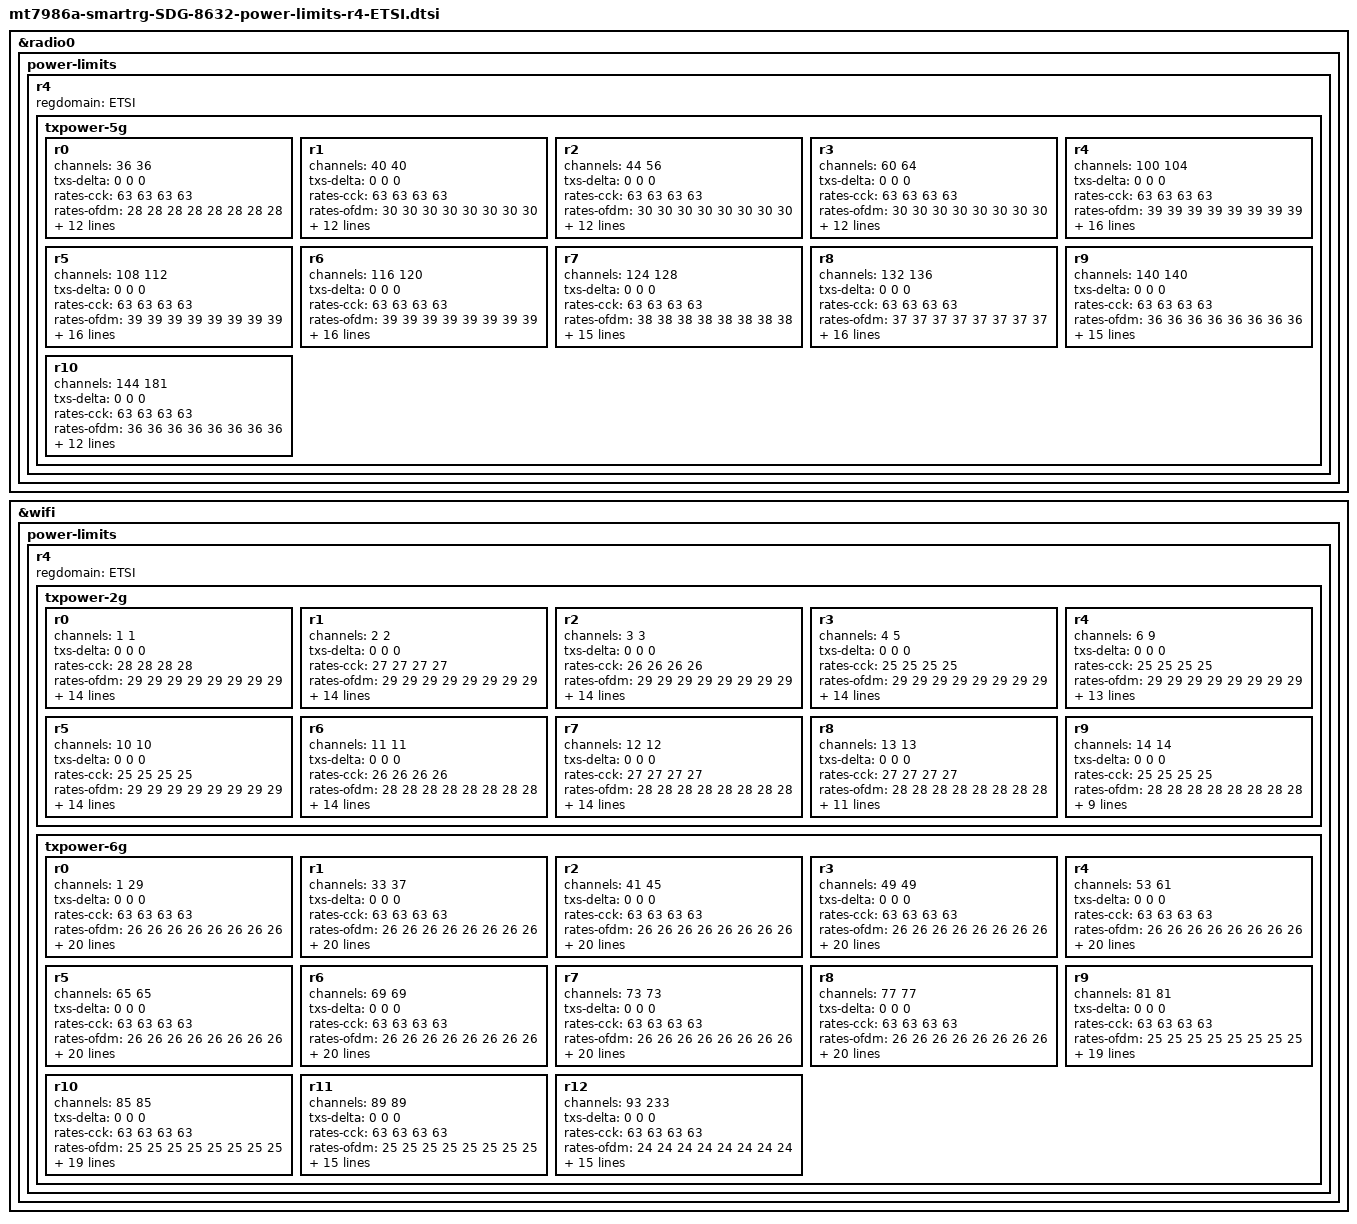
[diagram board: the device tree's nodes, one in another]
// SPDX-License-Identifier: (GPL-2.0 OR MIT)
/*
 * Copyright (C) 2022 SmartRG Inc.
 * Author: Chad Monroe <chad.monroe@smartrg.com>
 */

&radio0 {
	power-limits {
		r4 {
			regdomain = "ETSI";

			txpower-5g {
				r0 {
					channels = <36 36>;
					txs-delta = <0 0 0>;
					rates-cck = /bits/ 8 <63 63 63 63>;
					rates-ofdm = /bits/ 8 <28 28 28 28 28 28 28 28>;
					rates-mcs =
					/bits/ 8 <2 34 34 34 34 34 34 34 34 34 34>,
					/bits/ 8 <2 33 33 33 33 33 33 33 33 33 33>;
					rates-ru =
					/bits/ 8 <5 34 34 34 34 34 34 34 34 34 34 34 34>,
					/bits/ 8 <2 33 33 33 33 33 33 33 33 33 33 33 33>;
					paths-ofdm = /bits/ 8 <28 28 28 28>;
					paths-ofdm-bf = /bits/ 8 <0 28 28 28>;
					paths-ru =
					/bits/ 8 <5 34 34 34 34 34 34 34 34 34 34>,
					/bits/ 8 <2 33 33 33 33 33 33 33 33 33 33>;
					paths-ru-bf =
					/bits/ 8 <3 31 31 31 31 31 31 31 31 31 31>,
					/bits/ 8 <2 0 31 31 31 31 31 31 31 31 31>,
					/bits/ 8 <2 0 30 30 30 30 30 30 30 30 30>;
				};
				r1 {
					channels = <40 40>;
					txs-delta = <0 0 0>;
					rates-cck = /bits/ 8 <63 63 63 63>;
					rates-ofdm = /bits/ 8 <30 30 30 30 30 30 30 30>;
					rates-mcs =
					/bits/ 8 <2 34 34 34 34 34 34 34 34 34 34>,
					/bits/ 8 <2 33 33 33 33 33 33 33 33 33 33>;
					rates-ru =
					/bits/ 8 <5 34 34 34 34 34 34 34 34 34 34 34 34>,
					/bits/ 8 <2 33 33 33 33 33 33 33 33 33 33 33 33>;
					paths-ofdm = /bits/ 8 <30 30 30 30>;
					paths-ofdm-bf = /bits/ 8 <0 30 30 30>;
					paths-ru =
					/bits/ 8 <5 34 34 34 34 34 34 34 34 34 34>,
					/bits/ 8 <2 33 33 33 33 33 33 33 33 33 33>;
					paths-ru-bf =
					/bits/ 8 <3 31 31 31 31 31 31 31 31 31 31>,
					/bits/ 8 <2 0 31 31 31 31 31 31 31 31 31>,
					/bits/ 8 <2 0 30 30 30 30 30 30 30 30 30>;
				};
				r2 {
					channels = <44 56>;
					txs-delta = <0 0 0>;
					rates-cck = /bits/ 8 <63 63 63 63>;
					rates-ofdm = /bits/ 8 <30 30 30 30 30 30 30 30>;
					rates-mcs =
					/bits/ 8 <2 34 34 34 34 34 34 34 34 34 34>,
					/bits/ 8 <2 33 33 33 33 33 33 33 33 33 33>;
					rates-ru =
					/bits/ 8 <5 34 34 34 34 34 34 34 34 34 34 34 34>,
					/bits/ 8 <2 33 33 33 33 33 33 33 33 33 33 33 33>;
					paths-ofdm = /bits/ 8 <30 30 30 30>;
					paths-ofdm-bf = /bits/ 8 <0 30 30 30>;
					paths-ru =
					/bits/ 8 <5 34 34 34 34 34 34 34 34 34 34>,
					/bits/ 8 <2 33 33 33 33 33 33 33 33 33 33>;
					paths-ru-bf =
					/bits/ 8 <3 31 31 31 31 31 31 31 31 31 31>,
					/bits/ 8 <1 0 31 31 31 31 31 31 31 31 31>,
					/bits/ 8 <3 0 30 30 30 30 30 30 30 30 30>;
				};
				r3 {
					channels = <60 64>;
					txs-delta = <0 0 0>;
					rates-cck = /bits/ 8 <63 63 63 63>;
					rates-ofdm = /bits/ 8 <30 30 30 30 30 30 30 30>;
					rates-mcs =
					/bits/ 8 <1 34 34 34 34 34 34 34 34 34 34>,
					/bits/ 8 <3 33 33 33 33 33 33 33 33 33 33>;
					rates-ru =
					/bits/ 8 <4 34 34 34 34 34 34 34 34 34 34 34 34>,
					/bits/ 8 <3 33 33 33 33 33 33 33 33 33 33 33 33>;
					paths-ofdm = /bits/ 8 <30 30 30 30>;
					paths-ofdm-bf = /bits/ 8 <0 30 30 30>;
					paths-ru =
					/bits/ 8 <4 34 34 34 34 34 34 34 34 34 34>,
					/bits/ 8 <3 33 33 33 33 33 33 33 33 33 33>;
					paths-ru-bf =
					/bits/ 8 <3 31 31 31 31 31 31 31 31 31 31>,
					/bits/ 8 <1 0 31 31 31 31 31 31 31 31 31>,
					/bits/ 8 <3 0 30 30 30 30 30 30 30 30 30>;
				};
				r4 {
					channels = <100 104>;
					txs-delta = <0 0 0>;
					rates-cck = /bits/ 8 <63 63 63 63>;
					rates-ofdm = /bits/ 8 <39 39 39 39 39 39 39 39>;
					rates-mcs =
					/bits/ 8 <1 37 37 37 37 37 37 37 37 37 37>,
					/bits/ 8 <1 34 34 34 34 34 34 34 34 34 34>,
					/bits/ 8 <2 32 32 32 32 32 32 32 32 32 32>;
					rates-ru =
					/bits/ 8 <4 37 37 37 37 37 37 37 37 37 37 37 37>,
					/bits/ 8 <1 34 34 34 34 34 34 34 34 34 34 34 34>,
					/bits/ 8 <2 32 32 32 32 32 32 32 32 32 32 32 32>;
					paths-ofdm = /bits/ 8 <39 39 39 39>;
					paths-ofdm-bf = /bits/ 8 <0 39 39 39>;
					paths-ru =
					/bits/ 8 <4 37 37 37 37 37 37 37 37 37 37>,
					/bits/ 8 <1 34 34 34 34 34 34 34 34 34 34>,
					/bits/ 8 <2 32 32 32 32 32 32 32 32 32 32>;
					paths-ru-bf =
					/bits/ 8 <3 38 38 38 38 38 38 38 38 38 38>,
					/bits/ 8 <1 0 38 38 38 38 38 38 38 38 38>,
					/bits/ 8 <1 0 35 35 35 35 35 35 35 35 35>,
					/bits/ 8 <2 0 34 34 34 34 34 34 34 34 34>;
				};
				r5 {
					channels = <108 112>;
					txs-delta = <0 0 0>;
					rates-cck = /bits/ 8 <63 63 63 63>;
					rates-ofdm = /bits/ 8 <39 39 39 39 39 39 39 39>;
					rates-mcs =
					/bits/ 8 <1 37 37 37 37 37 37 37 37 37 37>,
					/bits/ 8 <1 35 35 35 35 35 35 35 35 35 35>,
					/bits/ 8 <2 32 32 32 32 32 32 32 32 32 32>;
					rates-ru =
					/bits/ 8 <4 37 37 37 37 37 37 37 37 37 37 37 37>,
					/bits/ 8 <1 35 35 35 35 35 35 35 35 35 35 35 35>,
					/bits/ 8 <2 32 32 32 32 32 32 32 32 32 32 32 32>;
					paths-ofdm = /bits/ 8 <39 39 39 39>;
					paths-ofdm-bf = /bits/ 8 <0 39 39 39>;
					paths-ru =
					/bits/ 8 <4 37 37 37 37 37 37 37 37 37 37>,
					/bits/ 8 <1 35 35 35 35 35 35 35 35 35 35>,
					/bits/ 8 <2 32 32 32 32 32 32 32 32 32 32>;
					paths-ru-bf =
					/bits/ 8 <3 38 38 38 38 38 38 38 38 38 38>,
					/bits/ 8 <1 0 38 38 38 38 38 38 38 38 38>,
					/bits/ 8 <1 0 36 36 36 36 36 36 36 36 36>,
					/bits/ 8 <2 0 34 34 34 34 34 34 34 34 34>;
				};
				r6 {
					channels = <116 120>;
					txs-delta = <0 0 0>;
					rates-cck = /bits/ 8 <63 63 63 63>;
					rates-ofdm = /bits/ 8 <39 39 39 39 39 39 39 39>;
					rates-mcs =
					/bits/ 8 <1 37 37 37 37 37 37 37 37 37 37>,
					/bits/ 8 <1 36 36 36 36 36 36 36 36 36 36>,
					/bits/ 8 <2 39 39 39 39 39 39 39 39 39 39>;
					rates-ru =
					/bits/ 8 <4 37 37 37 37 37 37 37 37 37 37 37 37>,
					/bits/ 8 <1 36 36 36 36 36 36 36 36 36 36 36 36>,
					/bits/ 8 <2 39 39 39 39 39 39 39 39 39 39 39 39>;
					paths-ofdm = /bits/ 8 <39 39 39 39>;
					paths-ofdm-bf = /bits/ 8 <0 39 39 39>;
					paths-ru =
					/bits/ 8 <4 37 37 37 37 37 37 37 37 37 37>,
					/bits/ 8 <1 36 36 36 36 36 36 36 36 36 36>,
					/bits/ 8 <2 39 39 39 39 39 39 39 39 39 39>;
					paths-ru-bf =
					/bits/ 8 <3 38 38 38 38 38 38 38 38 38 38>,
					/bits/ 8 <1 0 38 38 38 38 38 38 38 38 38>,
					/bits/ 8 <1 0 37 37 37 37 37 37 37 37 37>,
					/bits/ 8 <2 0 38 38 38 38 38 38 38 38 38>;
				};
				r7 {
					channels = <124 128>;
					txs-delta = <0 0 0>;
					rates-cck = /bits/ 8 <63 63 63 63>;
					rates-ofdm = /bits/ 8 <38 38 38 38 38 38 38 38>;
					rates-mcs =
					/bits/ 8 <1 36 36 36 36 36 36 36 36 36 36>,
					/bits/ 8 <1 37 37 37 37 37 37 37 37 37 37>,
					/bits/ 8 <2 39 39 39 39 39 39 39 39 39 39>;
					rates-ru =
					/bits/ 8 <4 36 36 36 36 36 36 36 36 36 36 36 36>,
					/bits/ 8 <1 37 37 37 37 37 37 37 37 37 37 37 37>,
					/bits/ 8 <2 39 39 39 39 39 39 39 39 39 39 39 39>;
					paths-ofdm = /bits/ 8 <38 38 38 38>;
					paths-ofdm-bf = /bits/ 8 <0 38 38 38>;
					paths-ru =
					/bits/ 8 <4 36 36 36 36 36 36 36 36 36 36>,
					/bits/ 8 <1 37 37 37 37 37 37 37 37 37 37>,
					/bits/ 8 <2 39 39 39 39 39 39 39 39 39 39>;
					paths-ru-bf =
					/bits/ 8 <3 37 37 37 37 37 37 37 37 37 37>,
					/bits/ 8 <1 0 37 37 37 37 37 37 37 37 37>,
					/bits/ 8 <3 0 38 38 38 38 38 38 38 38 38>;
				};
				r8 {
					channels = <132 136>;
					txs-delta = <0 0 0>;
					rates-cck = /bits/ 8 <63 63 63 63>;
					rates-ofdm = /bits/ 8 <37 37 37 37 37 37 37 37>;
					rates-mcs =
					/bits/ 8 <1 35 35 35 35 35 35 35 35 35 35>,
					/bits/ 8 <1 38 38 38 38 38 38 38 38 38 38>,
					/bits/ 8 <2 32 32 32 32 32 32 32 32 32 32>;
					rates-ru =
					/bits/ 8 <4 35 35 35 35 35 35 35 35 35 35 35 35>,
					/bits/ 8 <1 38 38 38 38 38 38 38 38 38 38 38 38>,
					/bits/ 8 <2 32 32 32 32 32 32 32 32 32 32 32 32>;
					paths-ofdm = /bits/ 8 <37 37 37 37>;
					paths-ofdm-bf = /bits/ 8 <0 37 37 37>;
					paths-ru =
					/bits/ 8 <4 35 35 35 35 35 35 35 35 35 35>,
					/bits/ 8 <1 38 38 38 38 38 38 38 38 38 38>,
					/bits/ 8 <2 32 32 32 32 32 32 32 32 32 32>;
					paths-ru-bf =
					/bits/ 8 <3 36 36 36 36 36 36 36 36 36 36>,
					/bits/ 8 <1 0 36 36 36 36 36 36 36 36 36>,
					/bits/ 8 <1 0 39 39 39 39 39 39 39 39 39>,
					/bits/ 8 <2 0 34 34 34 34 34 34 34 34 34>;
				};
				r9 {
					channels = <140 140>;
					txs-delta = <0 0 0>;
					rates-cck = /bits/ 8 <63 63 63 63>;
					rates-ofdm = /bits/ 8 <36 36 36 36 36 36 36 36>;
					rates-mcs =
					/bits/ 8 <1 34 34 34 34 34 34 34 34 34 34>,
					/bits/ 8 <1 38 38 38 38 38 38 38 38 38 38>,
					/bits/ 8 <2 32 32 32 32 32 32 32 32 32 32>;
					rates-ru =
					/bits/ 8 <4 34 34 34 34 34 34 34 34 34 34 34 34>,
					/bits/ 8 <1 38 38 38 38 38 38 38 38 38 38 38 38>,
					/bits/ 8 <2 32 32 32 32 32 32 32 32 32 32 32 32>;
					paths-ofdm = /bits/ 8 <36 36 36 36>;
					paths-ofdm-bf = /bits/ 8 <0 36 36 36>;
					paths-ru =
					/bits/ 8 <4 34 34 34 34 34 34 34 34 34 34>,
					/bits/ 8 <1 38 38 38 38 38 38 38 38 38 38>,
					/bits/ 8 <2 32 32 32 32 32 32 32 32 32 32>;
					paths-ru-bf =
					/bits/ 8 <3 35 35 35 35 35 35 35 35 35 35>,
					/bits/ 8 <2 0 35 35 35 35 35 35 35 35 35>,
					/bits/ 8 <2 0 34 34 34 34 34 34 34 34 34>;
				};
				r10 {
					channels = <144 181>;
					txs-delta = <0 0 0>;
					rates-cck = /bits/ 8 <63 63 63 63>;
					rates-ofdm = /bits/ 8 <36 36 36 36 36 36 36 36>;
					rates-mcs =
					/bits/ 8 <2 34 34 34 34 34 34 34 34 34 34>,
					/bits/ 8 <2 32 32 32 32 32 32 32 32 32 32>;
					rates-ru =
					/bits/ 8 <5 34 34 34 34 34 34 34 34 34 34 34 34>,
					/bits/ 8 <2 32 32 32 32 32 32 32 32 32 32 32 32>;
					paths-ofdm = /bits/ 8 <36 36 36 36>;
					paths-ofdm-bf = /bits/ 8 <0 36 36 36>;
					paths-ru =
					/bits/ 8 <5 34 34 34 34 34 34 34 34 34 34>,
					/bits/ 8 <2 32 32 32 32 32 32 32 32 32 32>;
					paths-ru-bf =
					/bits/ 8 <3 35 35 35 35 35 35 35 35 35 35>,
					/bits/ 8 <2 0 35 35 35 35 35 35 35 35 35>,
					/bits/ 8 <2 0 34 34 34 34 34 34 34 34 34>;
				};
			};
		};
	};
};

&wifi {
	power-limits {
		r4 {
			regdomain = "ETSI";

			txpower-2g {
				r0 {
					channels = <1 1>;
					txs-delta = <0 0 0>;
					rates-cck = /bits/ 8 <28 28 28 28>;
					rates-ofdm = /bits/ 8 <29 29 29 29 29 29 29 29>;
					rates-mcs =
					/bits/ 8 <1 29 29 29 29 29 29 29 29 29 29>,
					/bits/ 8 <3 31 31 31 31 31 31 31 31 31 31>;
					rates-ru =
					/bits/ 8 <4 29 29 29 29 29 29 29 29 29 29 29 29>,
					/bits/ 8 <3 31 31 31 31 31 31 31 31 31 31 31 31>;
					paths-cck = /bits/ 8 <28 28 28 28>;
					paths-ofdm = /bits/ 8 <29 29 29 29>;
					paths-ofdm-bf = /bits/ 8 <0 29 29 29>;
					paths-ru =
					/bits/ 8 <4 29 29 29 29 29 29 29 29 29 29>,
					/bits/ 8 <1 31 31 31 31 31 31 31 31 31 31>,
					/bits/ 8 <2 27 27 27 27 27 27 27 27 27 27>;
					paths-ru-bf =
					/bits/ 8 <3 26 26 26 26 26 26 26 26 26 26>,
					/bits/ 8 <1 0 26 26 26 26 26 26 26 26 26>,
					/bits/ 8 <3 0 27 27 27 27 27 27 27 27 27>;
				};
				r1 {
					channels = <2 2>;
					txs-delta = <0 0 0>;
					rates-cck = /bits/ 8 <27 27 27 27>;
					rates-ofdm = /bits/ 8 <29 29 29 29 29 29 29 29>;
					rates-mcs =
					/bits/ 8 <1 29 29 29 29 29 29 29 29 29 29>,
					/bits/ 8 <3 31 31 31 31 31 31 31 31 31 31>;
					rates-ru =
					/bits/ 8 <4 29 29 29 29 29 29 29 29 29 29 29 29>,
					/bits/ 8 <3 31 31 31 31 31 31 31 31 31 31 31 31>;
					paths-cck = /bits/ 8 <27 27 27 27>;
					paths-ofdm = /bits/ 8 <29 29 29 29>;
					paths-ofdm-bf = /bits/ 8 <0 29 29 29>;
					paths-ru =
					/bits/ 8 <4 29 29 29 29 29 29 29 29 29 29>,
					/bits/ 8 <1 31 31 31 31 31 31 31 31 31 31>,
					/bits/ 8 <2 27 27 27 27 27 27 27 27 27 27>;
					paths-ru-bf =
					/bits/ 8 <3 26 26 26 26 26 26 26 26 26 26>,
					/bits/ 8 <1 0 26 26 26 26 26 26 26 26 26>,
					/bits/ 8 <3 0 27 27 27 27 27 27 27 27 27>;
				};
				r2 {
					channels = <3 3>;
					txs-delta = <0 0 0>;
					rates-cck = /bits/ 8 <26 26 26 26>;
					rates-ofdm = /bits/ 8 <29 29 29 29 29 29 29 29>;
					rates-mcs =
					/bits/ 8 <1 29 29 29 29 29 29 29 29 29 29>,
					/bits/ 8 <3 31 31 31 31 31 31 31 31 31 31>;
					rates-ru =
					/bits/ 8 <4 29 29 29 29 29 29 29 29 29 29 29 29>,
					/bits/ 8 <3 31 31 31 31 31 31 31 31 31 31 31 31>;
					paths-cck = /bits/ 8 <26 26 26 26>;
					paths-ofdm = /bits/ 8 <29 29 29 29>;
					paths-ofdm-bf = /bits/ 8 <0 29 29 29>;
					paths-ru =
					/bits/ 8 <4 29 29 29 29 29 29 29 29 29 29>,
					/bits/ 8 <1 31 31 31 31 31 31 31 31 31 31>,
					/bits/ 8 <2 27 27 27 27 27 27 27 27 27 27>;
					paths-ru-bf =
					/bits/ 8 <3 26 26 26 26 26 26 26 26 26 26>,
					/bits/ 8 <1 0 26 26 26 26 26 26 26 26 26>,
					/bits/ 8 <3 0 27 27 27 27 27 27 27 27 27>;
				};
				r3 {
					channels = <4 5>;
					txs-delta = <0 0 0>;
					rates-cck = /bits/ 8 <25 25 25 25>;
					rates-ofdm = /bits/ 8 <29 29 29 29 29 29 29 29>;
					rates-mcs =
					/bits/ 8 <1 29 29 29 29 29 29 29 29 29 29>,
					/bits/ 8 <3 31 31 31 31 31 31 31 31 31 31>;
					rates-ru =
					/bits/ 8 <4 29 29 29 29 29 29 29 29 29 29 29 29>,
					/bits/ 8 <3 31 31 31 31 31 31 31 31 31 31 31 31>;
					paths-cck = /bits/ 8 <25 25 25 25>;
					paths-ofdm = /bits/ 8 <29 29 29 29>;
					paths-ofdm-bf = /bits/ 8 <0 29 29 29>;
					paths-ru =
					/bits/ 8 <4 29 29 29 29 29 29 29 29 29 29>,
					/bits/ 8 <1 31 31 31 31 31 31 31 31 31 31>,
					/bits/ 8 <2 26 26 26 26 26 26 26 26 26 26>;
					paths-ru-bf =
					/bits/ 8 <3 25 25 25 25 25 25 25 25 25 25>,
					/bits/ 8 <1 0 25 25 25 25 25 25 25 25 25>,
					/bits/ 8 <3 0 26 26 26 26 26 26 26 26 26>;
				};
				r4 {
					channels = <6 9>;
					txs-delta = <0 0 0>;
					rates-cck = /bits/ 8 <25 25 25 25>;
					rates-ofdm = /bits/ 8 <29 29 29 29 29 29 29 29>;
					rates-mcs =
					/bits/ 8 <1 28 28 28 28 28 28 28 28 28 28>,
					/bits/ 8 <3 30 30 30 30 30 30 30 30 30 30>;
					rates-ru =
					/bits/ 8 <4 28 28 28 28 28 28 28 28 28 28 28 28>,
					/bits/ 8 <3 30 30 30 30 30 30 30 30 30 30 30 30>;
					paths-cck = /bits/ 8 <25 25 25 25>;
					paths-ofdm = /bits/ 8 <29 29 29 29>;
					paths-ofdm-bf = /bits/ 8 <0 29 29 29>;
					paths-ru =
					/bits/ 8 <4 28 28 28 28 28 28 28 28 28 28>,
					/bits/ 8 <1 30 30 30 30 30 30 30 30 30 30>,
					/bits/ 8 <2 25 25 25 25 25 25 25 25 25 25>;
					paths-ru-bf =
					/bits/ 8 <3 25 25 25 25 25 25 25 25 25 25>,
					/bits/ 8 <4 0 25 25 25 25 25 25 25 25 25>;
				};
				r5 {
					channels = <10 10>;
					txs-delta = <0 0 0>;
					rates-cck = /bits/ 8 <25 25 25 25>;
					rates-ofdm = /bits/ 8 <29 29 29 29 29 29 29 29>;
					rates-mcs =
					/bits/ 8 <1 28 28 28 28 28 28 28 28 28 28>,
					/bits/ 8 <3 30 30 30 30 30 30 30 30 30 30>;
					rates-ru =
					/bits/ 8 <4 28 28 28 28 28 28 28 28 28 28 28 28>,
					/bits/ 8 <3 30 30 30 30 30 30 30 30 30 30 30 30>;
					paths-cck = /bits/ 8 <25 25 25 25>;
					paths-ofdm = /bits/ 8 <29 29 29 29>;
					paths-ofdm-bf = /bits/ 8 <0 29 29 29>;
					paths-ru =
					/bits/ 8 <4 28 28 28 28 28 28 28 28 28 28>,
					/bits/ 8 <1 30 30 30 30 30 30 30 30 30 30>,
					/bits/ 8 <2 26 26 26 26 26 26 26 26 26 26>;
					paths-ru-bf =
					/bits/ 8 <3 25 25 25 25 25 25 25 25 25 25>,
					/bits/ 8 <1 0 25 25 25 25 25 25 25 25 25>,
					/bits/ 8 <3 0 26 26 26 26 26 26 26 26 26>;
				};
				r6 {
					channels = <11 11>;
					txs-delta = <0 0 0>;
					rates-cck = /bits/ 8 <26 26 26 26>;
					rates-ofdm = /bits/ 8 <28 28 28 28 28 28 28 28>;
					rates-mcs =
					/bits/ 8 <1 28 28 28 28 28 28 28 28 28 28>,
					/bits/ 8 <3 30 30 30 30 30 30 30 30 30 30>;
					rates-ru =
					/bits/ 8 <4 28 28 28 28 28 28 28 28 28 28 28 28>,
					/bits/ 8 <3 30 30 30 30 30 30 30 30 30 30 30 30>;
					paths-cck = /bits/ 8 <26 26 26 26>;
					paths-ofdm = /bits/ 8 <28 28 28 28>;
					paths-ofdm-bf = /bits/ 8 <0 28 28 28>;
					paths-ru =
					/bits/ 8 <4 28 28 28 28 28 28 28 28 28 28>,
					/bits/ 8 <1 30 30 30 30 30 30 30 30 30 30>,
					/bits/ 8 <2 26 26 26 26 26 26 26 26 26 26>;
					paths-ru-bf =
					/bits/ 8 <3 25 25 25 25 25 25 25 25 25 25>,
					/bits/ 8 <1 0 25 25 25 25 25 25 25 25 25>,
					/bits/ 8 <3 0 26 26 26 26 26 26 26 26 26>;
				};
				r7 {
					channels = <12 12>;
					txs-delta = <0 0 0>;
					rates-cck = /bits/ 8 <27 27 27 27>;
					rates-ofdm = /bits/ 8 <28 28 28 28 28 28 28 28>;
					rates-mcs =
					/bits/ 8 <1 28 28 28 28 28 28 28 28 28 28>,
					/bits/ 8 <3 29 29 29 29 29 29 29 29 29 29>;
					rates-ru =
					/bits/ 8 <4 28 28 28 28 28 28 28 28 28 28 28 28>,
					/bits/ 8 <3 29 29 29 29 29 29 29 29 29 29 29 29>;
					paths-cck = /bits/ 8 <27 27 27 27>;
					paths-ofdm = /bits/ 8 <28 28 28 28>;
					paths-ofdm-bf = /bits/ 8 <0 28 28 28>;
					paths-ru =
					/bits/ 8 <4 28 28 28 28 28 28 28 28 28 28>,
					/bits/ 8 <1 29 29 29 29 29 29 29 29 29 29>,
					/bits/ 8 <2 26 26 26 26 26 26 26 26 26 26>;
					paths-ru-bf =
					/bits/ 8 <3 25 25 25 25 25 25 25 25 25 25>,
					/bits/ 8 <1 0 25 25 25 25 25 25 25 25 25>,
					/bits/ 8 <3 0 26 26 26 26 26 26 26 26 26>;
				};
				r8 {
					channels = <13 13>;
					txs-delta = <0 0 0>;
					rates-cck = /bits/ 8 <27 27 27 27>;
					rates-ofdm = /bits/ 8 <28 28 28 28 28 28 28 28>;
					rates-mcs =
					/bits/ 8 <4 28 28 28 28 28 28 28 28 28 28>;
					rates-ru =
					/bits/ 8 <7 28 28 28 28 28 28 28 28 28 28 28 28>;
					paths-cck = /bits/ 8 <27 27 27 27>;
					paths-ofdm = /bits/ 8 <28 28 28 28>;
					paths-ofdm-bf = /bits/ 8 <0 28 28 28>;
					paths-ru =
					/bits/ 8 <5 28 28 28 28 28 28 28 28 28 28>,
					/bits/ 8 <2 26 26 26 26 26 26 26 26 26 26>;
					paths-ru-bf =
					/bits/ 8 <3 25 25 25 25 25 25 25 25 25 25>,
					/bits/ 8 <1 0 25 25 25 25 25 25 25 25 25>,
					/bits/ 8 <3 0 26 26 26 26 26 26 26 26 26>;
				};
				r9 {
					channels = <14 14>;
					txs-delta = <0 0 0>;
					rates-cck = /bits/ 8 <25 25 25 25>;
					rates-ofdm = /bits/ 8 <28 28 28 28 28 28 28 28>;
					rates-mcs =
					/bits/ 8 <4 28 28 28 28 28 28 28 28 28 28>;
					rates-ru =
					/bits/ 8 <7 28 28 28 28 28 28 28 28 28 28 28 28>;
					paths-cck = /bits/ 8 <25 25 25 25>;
					paths-ofdm = /bits/ 8 <25 25 25 25>;
					paths-ofdm-bf = /bits/ 8 <0 25 25 25>;
					paths-ru =
					/bits/ 8 <7 25 25 25 25 25 25 25 25 25 25>;
					paths-ru-bf =
					/bits/ 8 <3 25 25 25 25 25 25 25 25 25 25>,
					/bits/ 8 <4 0 25 25 25 25 25 25 25 25 25>;
				};
			};

			txpower-6g {
				r0 {
					channels = <1 29>;
					txs-delta = <0 0 0>;
					rates-cck = /bits/ 8 <63 63 63 63>;
					rates-ofdm = /bits/ 8 <26 26 26 26 26 26 26 26>;
					rates-mcs =
					/bits/ 8 <1 29 29 29 29 29 29 29 29 29 29>,
					/bits/ 8 <1 31 31 31 31 31 31 31 31 31 31>,
					/bits/ 8 <1 29 29 29 29 29 29 29 29 29 29>,
					/bits/ 8 <1 31 31 31 31 31 31 31 31 31 31>;
					rates-ru =
					/bits/ 8 <4 29 29 29 29 29 29 29 29 29 29 29 29>,
					/bits/ 8 <1 31 31 31 31 31 31 31 31 31 31 31 31>,
					/bits/ 8 <1 29 29 29 29 29 29 29 29 29 29 29 29>,
					/bits/ 8 <1 31 31 31 31 31 31 31 31 31 31 31 31>;
					paths-ofdm = /bits/ 8 <26 26 26 26>;
					paths-ofdm-bf = /bits/ 8 <0 26 26 26>;
					paths-ru =
					/bits/ 8 <4 29 29 29 29 29 29 29 29 29 29>,
					/bits/ 8 <1 31 31 31 31 31 31 31 31 31 31>,
					/bits/ 8 <1 29 29 29 29 29 29 29 29 29 29>,
					/bits/ 8 <1 31 31 31 31 31 31 31 31 31 31>;
					paths-ru-bf =
					/bits/ 8 <3 20 20 20 20 20 20 20 20 20 20>,
					/bits/ 8 <1 0 20 20 20 20 20 20 20 20 20>,
					/bits/ 8 <1 0 21 21 21 21 21 21 21 21 21>,
					/bits/ 8 <1 0 20 20 20 20 20 20 20 20 20>,
					/bits/ 8 <1 0 22 22 22 22 22 22 22 22 22>;
				};
				r1 {
					channels = <33 37>;
					txs-delta = <0 0 0>;
					rates-cck = /bits/ 8 <63 63 63 63>;
					rates-ofdm = /bits/ 8 <26 26 26 26 26 26 26 26>;
					rates-mcs =
					/bits/ 8 <1 29 29 29 29 29 29 29 29 29 29>,
					/bits/ 8 <1 31 31 31 31 31 31 31 31 31 31>,
					/bits/ 8 <1 29 29 29 29 29 29 29 29 29 29>,
					/bits/ 8 <1 31 31 31 31 31 31 31 31 31 31>;
					rates-ru =
					/bits/ 8 <4 29 29 29 29 29 29 29 29 29 29 29 29>,
					/bits/ 8 <1 31 31 31 31 31 31 31 31 31 31 31 31>,
					/bits/ 8 <1 29 29 29 29 29 29 29 29 29 29 29 29>,
					/bits/ 8 <1 31 31 31 31 31 31 31 31 31 31 31 31>;
					paths-ofdm = /bits/ 8 <26 26 26 26>;
					paths-ofdm-bf = /bits/ 8 <0 26 26 26>;
					paths-ru =
					/bits/ 8 <4 29 29 29 29 29 29 29 29 29 29>,
					/bits/ 8 <1 31 31 31 31 31 31 31 31 31 31>,
					/bits/ 8 <1 29 29 29 29 29 29 29 29 29 29>,
					/bits/ 8 <1 31 31 31 31 31 31 31 31 31 31>;
					paths-ru-bf =
					/bits/ 8 <3 20 20 20 20 20 20 20 20 20 20>,
					/bits/ 8 <1 0 20 20 20 20 20 20 20 20 20>,
					/bits/ 8 <1 0 21 21 21 21 21 21 21 21 21>,
					/bits/ 8 <1 0 20 20 20 20 20 20 20 20 20>,
					/bits/ 8 <1 0 21 21 21 21 21 21 21 21 21>;
				};
				r2 {
					channels = <41 45>;
					txs-delta = <0 0 0>;
					rates-cck = /bits/ 8 <63 63 63 63>;
					rates-ofdm = /bits/ 8 <26 26 26 26 26 26 26 26>;
					rates-mcs =
					/bits/ 8 <1 29 29 29 29 29 29 29 29 29 29>,
					/bits/ 8 <1 30 30 30 30 30 30 30 30 30 30>,
					/bits/ 8 <1 29 29 29 29 29 29 29 29 29 29>,
					/bits/ 8 <1 31 31 31 31 31 31 31 31 31 31>;
					rates-ru =
					/bits/ 8 <4 29 29 29 29 29 29 29 29 29 29 29 29>,
					/bits/ 8 <1 30 30 30 30 30 30 30 30 30 30 30 30>,
					/bits/ 8 <1 29 29 29 29 29 29 29 29 29 29 29 29>,
					/bits/ 8 <1 31 31 31 31 31 31 31 31 31 31 31 31>;
					paths-ofdm = /bits/ 8 <26 26 26 26>;
					paths-ofdm-bf = /bits/ 8 <0 26 26 26>;
					paths-ru =
					/bits/ 8 <4 29 29 29 29 29 29 29 29 29 29>,
					/bits/ 8 <1 30 30 30 30 30 30 30 30 30 30>,
					/bits/ 8 <1 29 29 29 29 29 29 29 29 29 29>,
					/bits/ 8 <1 31 31 31 31 31 31 31 31 31 31>;
					paths-ru-bf =
					/bits/ 8 <3 20 20 20 20 20 20 20 20 20 20>,
					/bits/ 8 <1 0 20 20 20 20 20 20 20 20 20>,
					/bits/ 8 <1 0 21 21 21 21 21 21 21 21 21>,
					/bits/ 8 <1 0 20 20 20 20 20 20 20 20 20>,
					/bits/ 8 <1 0 21 21 21 21 21 21 21 21 21>;
				};
				r3 {
					channels = <49 49>;
					txs-delta = <0 0 0>;
					rates-cck = /bits/ 8 <63 63 63 63>;
					rates-ofdm = /bits/ 8 <26 26 26 26 26 26 26 26>;
					rates-mcs =
					/bits/ 8 <1 29 29 29 29 29 29 29 29 29 29>,
					/bits/ 8 <1 30 30 30 30 30 30 30 30 30 30>,
					/bits/ 8 <1 29 29 29 29 29 29 29 29 29 29>,
					/bits/ 8 <1 31 31 31 31 31 31 31 31 31 31>;
					rates-ru =
					/bits/ 8 <4 29 29 29 29 29 29 29 29 29 29 29 29>,
					/bits/ 8 <1 30 30 30 30 30 30 30 30 30 30 30 30>,
					/bits/ 8 <1 29 29 29 29 29 29 29 29 29 29 29 29>,
					/bits/ 8 <1 31 31 31 31 31 31 31 31 31 31 31 31>;
					paths-ofdm = /bits/ 8 <26 26 26 26>;
					paths-ofdm-bf = /bits/ 8 <0 26 26 26>;
					paths-ru =
					/bits/ 8 <4 29 29 29 29 29 29 29 29 29 29>,
					/bits/ 8 <1 30 30 30 30 30 30 30 30 30 30>,
					/bits/ 8 <1 29 29 29 29 29 29 29 29 29 29>,
					/bits/ 8 <1 31 31 31 31 31 31 31 31 31 31>;
					paths-ru-bf =
					/bits/ 8 <3 20 20 20 20 20 20 20 20 20 20>,
					/bits/ 8 <1 0 20 20 20 20 20 20 20 20 20>,
					/bits/ 8 <1 0 21 21 21 21 21 21 21 21 21>,
					/bits/ 8 <1 0 19 19 19 19 19 19 19 19 19>,
					/bits/ 8 <1 0 21 21 21 21 21 21 21 21 21>;
				};
				r4 {
					channels = <53 61>;
					txs-delta = <0 0 0>;
					rates-cck = /bits/ 8 <63 63 63 63>;
					rates-ofdm = /bits/ 8 <26 26 26 26 26 26 26 26>;
					rates-mcs =
					/bits/ 8 <1 29 29 29 29 29 29 29 29 29 29>,
					/bits/ 8 <1 30 30 30 30 30 30 30 30 30 30>,
					/bits/ 8 <1 28 28 28 28 28 28 28 28 28 28>,
					/bits/ 8 <1 31 31 31 31 31 31 31 31 31 31>;
					rates-ru =
					/bits/ 8 <4 29 29 29 29 29 29 29 29 29 29 29 29>,
					/bits/ 8 <1 30 30 30 30 30 30 30 30 30 30 30 30>,
					/bits/ 8 <1 28 28 28 28 28 28 28 28 28 28 28 28>,
					/bits/ 8 <1 31 31 31 31 31 31 31 31 31 31 31 31>;
					paths-ofdm = /bits/ 8 <26 26 26 26>;
					paths-ofdm-bf = /bits/ 8 <0 26 26 26>;
					paths-ru =
					/bits/ 8 <4 29 29 29 29 29 29 29 29 29 29>,
					/bits/ 8 <1 30 30 30 30 30 30 30 30 30 30>,
					/bits/ 8 <1 28 28 28 28 28 28 28 28 28 28>,
					/bits/ 8 <1 31 31 31 31 31 31 31 31 31 31>;
					paths-ru-bf =
					/bits/ 8 <3 20 20 20 20 20 20 20 20 20 20>,
					/bits/ 8 <1 0 20 20 20 20 20 20 20 20 20>,
					/bits/ 8 <1 0 21 21 21 21 21 21 21 21 21>,
					/bits/ 8 <1 0 19 19 19 19 19 19 19 19 19>,
					/bits/ 8 <1 0 21 21 21 21 21 21 21 21 21>;
				};
				r5 {
					channels = <65 65>;
					txs-delta = <0 0 0>;
					rates-cck = /bits/ 8 <63 63 63 63>;
					rates-ofdm = /bits/ 8 <26 26 26 26 26 26 26 26>;
					rates-mcs =
					/bits/ 8 <1 28 28 28 28 28 28 28 28 28 28>,
					/bits/ 8 <1 30 30 30 30 30 30 30 30 30 30>,
					/bits/ 8 <1 28 28 28 28 28 28 28 28 28 28>,
					/bits/ 8 <1 31 31 31 31 31 31 31 31 31 31>;
					rates-ru =
					/bits/ 8 <4 28 28 28 28 28 28 28 28 28 28 28 28>,
					/bits/ 8 <1 30 30 30 30 30 30 30 30 30 30 30 30>,
					/bits/ 8 <1 28 28 28 28 28 28 28 28 28 28 28 28>,
					/bits/ 8 <1 31 31 31 31 31 31 31 31 31 31 31 31>;
					paths-ofdm = /bits/ 8 <26 26 26 26>;
					paths-ofdm-bf = /bits/ 8 <0 26 26 26>;
					paths-ru =
					/bits/ 8 <4 28 28 28 28 28 28 28 28 28 28>,
					/bits/ 8 <1 30 30 30 30 30 30 30 30 30 30>,
					/bits/ 8 <1 28 28 28 28 28 28 28 28 28 28>,
					/bits/ 8 <1 31 31 31 31 31 31 31 31 31 31>;
					paths-ru-bf =
					/bits/ 8 <3 20 20 20 20 20 20 20 20 20 20>,
					/bits/ 8 <1 0 20 20 20 20 20 20 20 20 20>,
					/bits/ 8 <1 0 21 21 21 21 21 21 21 21 21>,
					/bits/ 8 <1 0 18 18 18 18 18 18 18 18 18>,
					/bits/ 8 <1 0 20 20 20 20 20 20 20 20 20>;
				};
				r6 {
					channels = <69 69>;
					txs-delta = <0 0 0>;
					rates-cck = /bits/ 8 <63 63 63 63>;
					rates-ofdm = /bits/ 8 <26 26 26 26 26 26 26 26>;
					rates-mcs =
					/bits/ 8 <1 28 28 28 28 28 28 28 28 28 28>,
					/bits/ 8 <1 29 29 29 29 29 29 29 29 29 29>,
					/bits/ 8 <1 28 28 28 28 28 28 28 28 28 28>,
					/bits/ 8 <1 31 31 31 31 31 31 31 31 31 31>;
					rates-ru =
					/bits/ 8 <4 28 28 28 28 28 28 28 28 28 28 28 28>,
					/bits/ 8 <1 29 29 29 29 29 29 29 29 29 29 29 29>,
					/bits/ 8 <1 28 28 28 28 28 28 28 28 28 28 28 28>,
					/bits/ 8 <1 31 31 31 31 31 31 31 31 31 31 31 31>;
					paths-ofdm = /bits/ 8 <26 26 26 26>;
					paths-ofdm-bf = /bits/ 8 <0 26 26 26>;
					paths-ru =
					/bits/ 8 <4 28 28 28 28 28 28 28 28 28 28>,
					/bits/ 8 <1 29 29 29 29 29 29 29 29 29 29>,
					/bits/ 8 <1 28 28 28 28 28 28 28 28 28 28>,
					/bits/ 8 <1 31 31 31 31 31 31 31 31 31 31>;
					paths-ru-bf =
					/bits/ 8 <3 20 20 20 20 20 20 20 20 20 20>,
					/bits/ 8 <1 0 20 20 20 20 20 20 20 20 20>,
					/bits/ 8 <1 0 21 21 21 21 21 21 21 21 21>,
					/bits/ 8 <1 0 18 18 18 18 18 18 18 18 18>,
					/bits/ 8 <1 0 20 20 20 20 20 20 20 20 20>;
				};
				r7 {
					channels = <73 73>;
					txs-delta = <0 0 0>;
					rates-cck = /bits/ 8 <63 63 63 63>;
					rates-ofdm = /bits/ 8 <26 26 26 26 26 26 26 26>;
					rates-mcs =
					/bits/ 8 <1 28 28 28 28 28 28 28 28 28 28>,
					/bits/ 8 <1 29 29 29 29 29 29 29 29 29 29>,
					/bits/ 8 <1 28 28 28 28 28 28 28 28 28 28>,
					/bits/ 8 <1 31 31 31 31 31 31 31 31 31 31>;
					rates-ru =
					/bits/ 8 <4 28 28 28 28 28 28 28 28 28 28 28 28>,
					/bits/ 8 <1 29 29 29 29 29 29 29 29 29 29 29 29>,
					/bits/ 8 <1 28 28 28 28 28 28 28 28 28 28 28 28>,
					/bits/ 8 <1 31 31 31 31 31 31 31 31 31 31 31 31>;
					paths-ofdm = /bits/ 8 <26 26 26 26>;
					paths-ofdm-bf = /bits/ 8 <0 26 26 26>;
					paths-ru =
					/bits/ 8 <4 28 28 28 28 28 28 28 28 28 28>,
					/bits/ 8 <1 29 29 29 29 29 29 29 29 29 29>,
					/bits/ 8 <1 28 28 28 28 28 28 28 28 28 28>,
					/bits/ 8 <1 31 31 31 31 31 31 31 31 31 31>;
					paths-ru-bf =
					/bits/ 8 <3 19 19 19 19 19 19 19 19 19 19>,
					/bits/ 8 <1 0 19 19 19 19 19 19 19 19 19>,
					/bits/ 8 <1 0 20 20 20 20 20 20 20 20 20>,
					/bits/ 8 <1 0 18 18 18 18 18 18 18 18 18>,
					/bits/ 8 <1 0 20 20 20 20 20 20 20 20 20>;
				};
				r8 {
					channels = <77 77>;
					txs-delta = <0 0 0>;
					rates-cck = /bits/ 8 <63 63 63 63>;
					rates-ofdm = /bits/ 8 <26 26 26 26 26 26 26 26>;
					rates-mcs =
					/bits/ 8 <1 27 27 27 27 27 27 27 27 27 27>,
					/bits/ 8 <1 29 29 29 29 29 29 29 29 29 29>,
					/bits/ 8 <1 28 28 28 28 28 28 28 28 28 28>,
					/bits/ 8 <1 31 31 31 31 31 31 31 31 31 31>;
					rates-ru =
					/bits/ 8 <4 27 27 27 27 27 27 27 27 27 27 27 27>,
					/bits/ 8 <1 29 29 29 29 29 29 29 29 29 29 29 29>,
					/bits/ 8 <1 28 28 28 28 28 28 28 28 28 28 28 28>,
					/bits/ 8 <1 31 31 31 31 31 31 31 31 31 31 31 31>;
					paths-ofdm = /bits/ 8 <26 26 26 26>;
					paths-ofdm-bf = /bits/ 8 <0 26 26 26>;
					paths-ru =
					/bits/ 8 <4 27 27 27 27 27 27 27 27 27 27>,
					/bits/ 8 <1 29 29 29 29 29 29 29 29 29 29>,
					/bits/ 8 <1 28 28 28 28 28 28 28 28 28 28>,
					/bits/ 8 <1 31 31 31 31 31 31 31 31 31 31>;
					paths-ru-bf =
					/bits/ 8 <3 19 19 19 19 19 19 19 19 19 19>,
					/bits/ 8 <1 0 19 19 19 19 19 19 19 19 19>,
					/bits/ 8 <1 0 20 20 20 20 20 20 20 20 20>,
					/bits/ 8 <1 0 18 18 18 18 18 18 18 18 18>,
					/bits/ 8 <1 0 20 20 20 20 20 20 20 20 20>;
				};
				r9 {
					channels = <81 81>;
					txs-delta = <0 0 0>;
					rates-cck = /bits/ 8 <63 63 63 63>;
					rates-ofdm = /bits/ 8 <25 25 25 25 25 25 25 25>;
					rates-mcs =
					/bits/ 8 <1 27 27 27 27 27 27 27 27 27 27>,
					/bits/ 8 <1 29 29 29 29 29 29 29 29 29 29>,
					/bits/ 8 <1 28 28 28 28 28 28 28 28 28 28>,
					/bits/ 8 <1 31 31 31 31 31 31 31 31 31 31>;
					rates-ru =
					/bits/ 8 <4 27 27 27 27 27 27 27 27 27 27 27 27>,
					/bits/ 8 <1 29 29 29 29 29 29 29 29 29 29 29 29>,
					/bits/ 8 <1 28 28 28 28 28 28 28 28 28 28 28 28>,
					/bits/ 8 <1 31 31 31 31 31 31 31 31 31 31 31 31>;
					paths-ofdm = /bits/ 8 <25 25 25 25>;
					paths-ofdm-bf = /bits/ 8 <0 25 25 25>;
					paths-ru =
					/bits/ 8 <4 27 27 27 27 27 27 27 27 27 27>,
					/bits/ 8 <1 29 29 29 29 29 29 29 29 29 29>,
					/bits/ 8 <1 28 28 28 28 28 28 28 28 28 28>,
					/bits/ 8 <1 31 31 31 31 31 31 31 31 31 31>;
					paths-ru-bf =
					/bits/ 8 <3 18 18 18 18 18 18 18 18 18 18>,
					/bits/ 8 <2 0 18 18 18 18 18 18 18 18 18>,
					/bits/ 8 <1 0 17 17 17 17 17 17 17 17 17>,
					/bits/ 8 <1 0 20 20 20 20 20 20 20 20 20>;
				};
				r10 {
					channels = <85 85>;
					txs-delta = <0 0 0>;
					rates-cck = /bits/ 8 <63 63 63 63>;
					rates-ofdm = /bits/ 8 <25 25 25 25 25 25 25 25>;
					rates-mcs =
					/bits/ 8 <1 26 26 26 26 26 26 26 26 26 26>,
					/bits/ 8 <1 29 29 29 29 29 29 29 29 29 29>,
					/bits/ 8 <1 28 28 28 28 28 28 28 28 28 28>,
					/bits/ 8 <1 31 31 31 31 31 31 31 31 31 31>;
					rates-ru =
					/bits/ 8 <4 26 26 26 26 26 26 26 26 26 26 26 26>,
					/bits/ 8 <1 29 29 29 29 29 29 29 29 29 29 29 29>,
					/bits/ 8 <1 28 28 28 28 28 28 28 28 28 28 28 28>,
					/bits/ 8 <1 31 31 31 31 31 31 31 31 31 31 31 31>;
					paths-ofdm = /bits/ 8 <25 25 25 25>;
					paths-ofdm-bf = /bits/ 8 <0 25 25 25>;
					paths-ru =
					/bits/ 8 <4 26 26 26 26 26 26 26 26 26 26>,
					/bits/ 8 <1 29 29 29 29 29 29 29 29 29 29>,
					/bits/ 8 <1 28 28 28 28 28 28 28 28 28 28>,
					/bits/ 8 <1 31 31 31 31 31 31 31 31 31 31>;
					paths-ru-bf =
					/bits/ 8 <3 18 18 18 18 18 18 18 18 18 18>,
					/bits/ 8 <2 0 18 18 18 18 18 18 18 18 18>,
					/bits/ 8 <1 0 17 17 17 17 17 17 17 17 17>,
					/bits/ 8 <1 0 20 20 20 20 20 20 20 20 20>;
				};
				r11 {
					channels = <89 89>;
					txs-delta = <0 0 0>;
					rates-cck = /bits/ 8 <63 63 63 63>;
					rates-ofdm = /bits/ 8 <25 25 25 25 25 25 25 25>;
					rates-mcs =
					/bits/ 8 <1 26 26 26 26 26 26 26 26 26 26>,
					/bits/ 8 <2 28 28 28 28 28 28 28 28 28 28>,
					/bits/ 8 <1 31 31 31 31 31 31 31 31 31 31>;
					rates-ru =
					/bits/ 8 <4 26 26 26 26 26 26 26 26 26 26 26 26>,
					/bits/ 8 <2 28 28 28 28 28 28 28 28 28 28 28 28>,
					/bits/ 8 <1 31 31 31 31 31 31 31 31 31 31 31 31>;
					paths-ofdm = /bits/ 8 <25 25 25 25>;
					paths-ofdm-bf = /bits/ 8 <0 25 25 25>;
					paths-ru =
					/bits/ 8 <4 26 26 26 26 26 26 26 26 26 26>,
					/bits/ 8 <2 28 28 28 28 28 28 28 28 28 28>,
					/bits/ 8 <1 31 31 31 31 31 31 31 31 31 31>;
					paths-ru-bf =
					/bits/ 8 <3 17 17 17 17 17 17 17 17 17 17>,
					/bits/ 8 <3 0 17 17 17 17 17 17 17 17 17>,
					/bits/ 8 <1 0 20 20 20 20 20 20 20 20 20>;
				};
				r12 {
					channels = <93 233>;
					txs-delta = <0 0 0>;
					rates-cck = /bits/ 8 <63 63 63 63>;
					rates-ofdm = /bits/ 8 <24 24 24 24 24 24 24 24>;
					rates-mcs =
					/bits/ 8 <1 26 26 26 26 26 26 26 26 26 26>,
					/bits/ 8 <2 28 28 28 28 28 28 28 28 28 28>,
					/bits/ 8 <1 31 31 31 31 31 31 31 31 31 31>;
					rates-ru =
					/bits/ 8 <4 26 26 26 26 26 26 26 26 26 26 26 26>,
					/bits/ 8 <2 28 28 28 28 28 28 28 28 28 28 28 28>,
					/bits/ 8 <1 31 31 31 31 31 31 31 31 31 31 31 31>;
					paths-ofdm = /bits/ 8 <24 24 24 24>;
					paths-ofdm-bf = /bits/ 8 <0 24 24 24>;
					paths-ru =
					/bits/ 8 <4 26 26 26 26 26 26 26 26 26 26>,
					/bits/ 8 <2 28 28 28 28 28 28 28 28 28 28>,
					/bits/ 8 <1 31 31 31 31 31 31 31 31 31 31>;
					paths-ru-bf =
					/bits/ 8 <3 17 17 17 17 17 17 17 17 17 17>,
					/bits/ 8 <3 0 17 17 17 17 17 17 17 17 17>,
					/bits/ 8 <1 0 20 20 20 20 20 20 20 20 20>;
				};
			};
		};
	};
};
